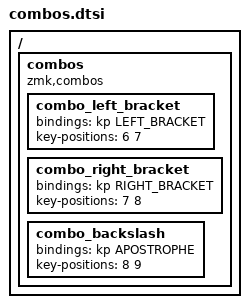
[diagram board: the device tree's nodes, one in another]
/ {
    combos {
        compatible = "zmk,combos";
        
        combo_left_bracket {
            bindings = <&kp LEFT_BRACKET>;
            key-positions = <6 7>;
        };
        
        combo_right_bracket {
            bindings = <&kp RIGHT_BRACKET>;
            key-positions = <7 8>;
        };
        
        combo_backslash {
            bindings = <&kp APOSTROPHE>;
            key-positions = <8 9>;
        };
    };
};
